# CH32X035 register map
Vendor: WCH Ltd.; File version: 1.3
Registers are 32-bit, read-write, reset 0x0 unless marked. A register's access mark holds for its fields unless they carry their own. Offsets are from the block's base; [hi:lo] are bit positions; {n}, {i} and the like mark numbered series.

## GPIOA — General purpose I/O
Base 0x40010800
Same registers: GPIOB 0x40010C00, GPIOC 0x40011000
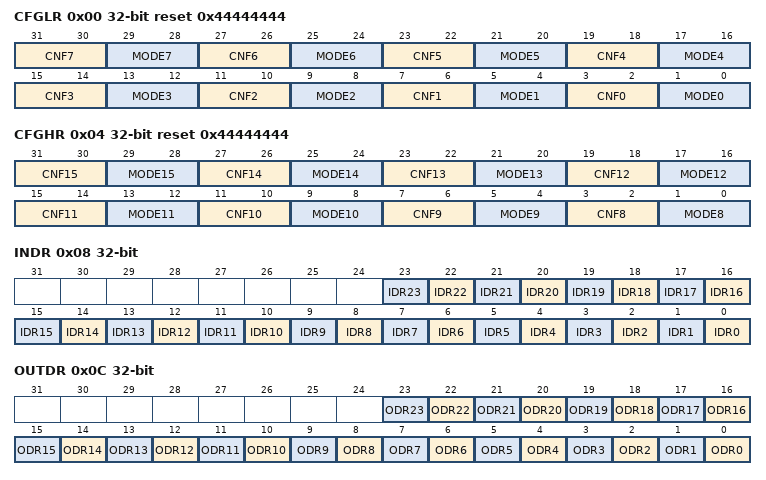
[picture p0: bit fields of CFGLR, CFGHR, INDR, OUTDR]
0x00 CFGLR reset 0x44444444 — Port configuration register low (GPIOn_CFGLR)
  [31:30] CNF7 — Port n.7 configuration bits
  [29:28] MODE7 — Port n.7 mode bits
  [27:26] CNF6 — Port n.6 configuration bits
  [25:24] MODE6 — Port n.6 mode bits
  [23:22] CNF5 — Port n.5 configuration bits
  [21:20] MODE5 — Port n.5 mode bits
  [19:18] CNF4 — Port n.4 configuration bits
  [17:16] MODE4 — Port n.4 mode bits
  [15:14] CNF3 — Port n.3 configuration bits
  [13:12] MODE3 — Port n.3 mode bits
  [11:10] CNF2 — Port n.2 configuration bits
  [9:8] MODE2 — Port n.2 mode bits
  [7:6] CNF1 — Port n.1 configuration bits
  [5:4] MODE1 — Port n.1 mode bits
  [3:2] CNF0 — Port n.0 configuration bits
  [1:0] MODE0 — Port n.0 mode bits
0x04 CFGHR reset 0x44444444 — Port configuration register high (GPIOn_CFGHR)
  [31:30] CNF15 — Port n.15 configuration bits
  [29:28] MODE15 — Port n.15 mode bits
  [27:26] CNF14 — Port n.14 configuration bits
  [25:24] MODE14 — Port n.14 mode bits
  [23:22] CNF13 — Port n.13 configuration bits
  [21:20] MODE13 — Port n.13 mode bits
  [19:18] CNF12 — Port n.12 configuration bits
  [17:16] MODE12 — Port n.12 mode bits
  [15:14] CNF11 — Port n.11 configuration bits
  [13:12] MODE11 — Port n.11 mode bits
  [11:10] CNF10 — Port n.10 configuration bits
  [9:8] MODE10 — Port n.10 mode bits
  [7:6] CNF9 — Port n.9 configuration bits
  [5:4] MODE9 — Port n.9 mode bits
  [3:2] CNF8 — Port n.8 configuration bits
  [1:0] MODE8 — Port n.8 mode bits
0x08 INDR ro — Port input data register (GPIOn_INDR)
  [n] IDR{n} (n=0..23) — Port input data
0x0C OUTDR — Port output data register (GPIOn_OUTDR)
  [n] ODR{n} (n=0..23) — Port output data
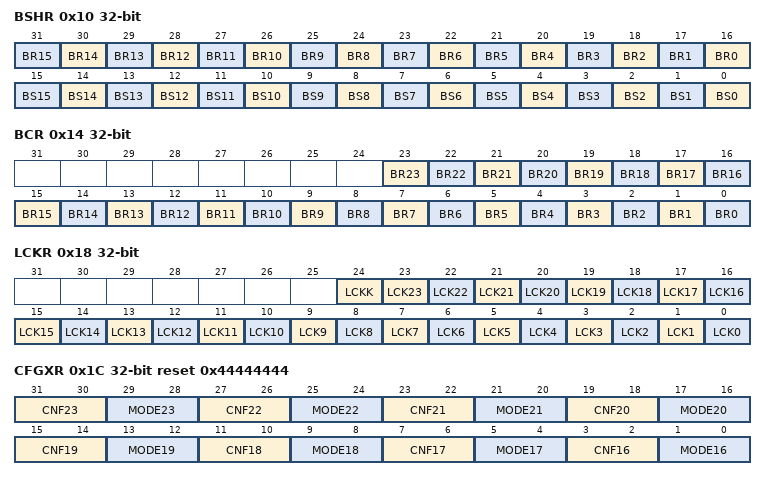
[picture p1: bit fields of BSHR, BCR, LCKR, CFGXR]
0x10 BSHR wo — Port bit set/reset register (GPIOn_BSHR)
  [n+16] BR{n} (n=0..15) — Reset bit {n}
  [n] BS{n} (n=0..15) — Set bit {n}
0x14 BCR wo — Port bit reset register (GPIOn_BCR)
  [n] BR{n} (n=3..23) — Reset bit {n}
  [2] BR2 — Reset bit 1
  [1] BR1 — Reset bit 1
  [0] BR0 — Reset bit 0
0x18 LCKR access per field — Port configuration lock register
  [24] LCKK ro — Lock key
  [n] LCK{n} rw (n=0..23) — Port A Lock bit {n}
0x1C CFGXR reset 0x44444444 — Port configuration register extension (GPIOn_CFGXR)
  [31:30] CNF23 — Port n.23 configuration bits
  [29:28] MODE23 — Port n.23 mode bits
  [27:26] CNF22 — Port n.22 configuration bits
  [25:24] MODE22 — Port n.22 mode bits
  [23:22] CNF21 — Port n.21 configuration bits
  [21:20] MODE21 — Port n.21 mode bits
  [19:18] CNF20 — Port n.20 configuration bits
  [17:16] MODE20 — Port n.20 mode bits
  [15:14] CNF19 — Port n.19 configuration bits
  [13:12] MODE19 — Port n.19 mode bits
  [11:10] CNF18 — Port n.18 configuration bits
  [9:8] MODE18 — Port n.18 mode bits
  [7:6] CNF17 — Port n.17 configuration bits
  [5:4] MODE17 — Port n.17 mode bits
  [3:2] CNF16 — Port n.16 configuration bits
  [1:0] MODE16 — Port n.16 mode bits
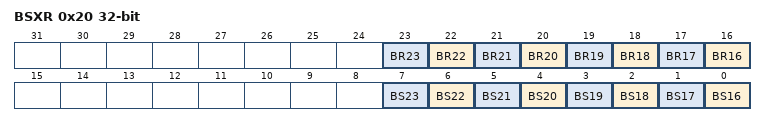
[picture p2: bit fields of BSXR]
0x20 BSXR wo — Port bit set/reset register (GPIOn_BSXR)
  [n] BR{n} (n=16..23) — Reset bit {n}
  [n-16] BS{n} (n=16..23) — Set bit {n}

## AFIO — Alternate function I/O
Base 0x40010000
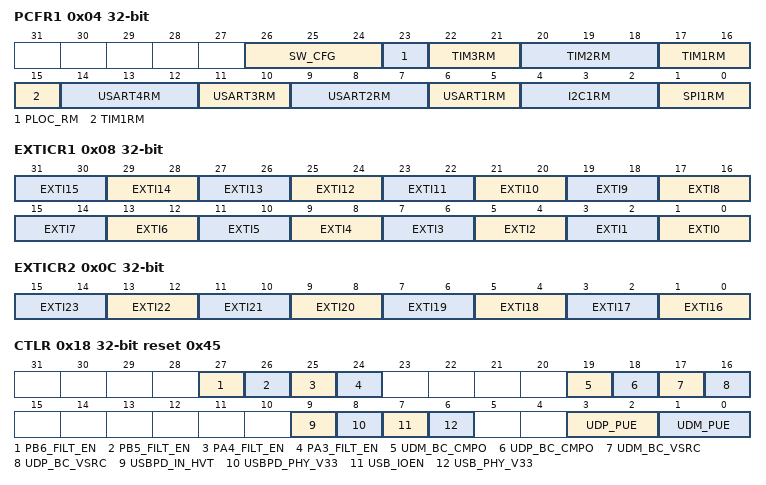
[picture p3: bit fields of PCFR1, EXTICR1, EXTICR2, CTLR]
0x04 PCFR1 — AF remap and debug I/O configuration register (AFIO_PCFR1)
  [26:24] SW_CFG — SW_CFG Configuration
  [23] PLOC_RM — IO2W_RM remapping
  [22:21] TIM3RM — TIM3 remapping
  [20:18] TIM2RM — TIM2 remapping
  [17:15] TIM1RM — TIM1 remapping
  [14:12] USART4RM — USART4 remapping
  [11:10] USART3RM — USART3 remapping
  [9:7] USART2RM — USART2 remapping
  [6:5] USART1RM — USART1 remapping
  [4:2] I2C1RM — I2C1 remapping
  [1:0] SPI1RM — SPI1 remapping
0x08 EXTICR1 — External interrupt configuration register 1 (AFIO_EXTICR1)
  [2n+1:2n] EXTI{n} (n=0..15) — EXTI{n} configuration
0x0C EXTICR2 — External interrupt configuration register 2 (AFIO_EXTICR2)
  [2n-31:2n-32] EXTI{n} (n=16..23) — EXTI{n} configuration
0x18 CTLR access per field reset 0x45 — control register
  [27] PB6_FILT_EN rw — PB6_FILT_EN configuration
  [26] PB5_FILT_EN rw — PB5_FILT_EN configuration
  [25] PA4_FILT_EN rw — PA4_FILT_EN configuration
  [24] PA3_FILT_EN rw — PA3_FILT_EN configuration
  [19] UDM_BC_CMPO ro — UDM_BC_CMPO configuration
  [18] UDP_BC_CMPO ro — UDP_BC_CMPO configuration
  [17] UDM_BC_VSRC rw — UDM_BC_VSRC configuration
  [16] UDP_BC_VSRC rw — UDP_BC_VSRC configuration
  [9] USBPD_IN_HVT rw — USBPD_IN_HVT configuration
  [8] USBPD_PHY_V33 rw — USBPD_PHY_V33 configuration
  [7] USB_IOEN rw — USB_IOEN configuration
  [6] USB_PHY_V33 rw — USB_PHY_V33 configuration
  [3:2] UDP_PUE rw — UDP_PUE configuration
  [1:0] UDM_PUE rw — UDM_PUE configuration
